# GBA register map
File version: 0.5
Registers are 16-bit, read-write, reset 0x0 unless marked. A register's access mark holds for its fields unless they carry their own. Offsets are from the block's base; [hi:lo] are bit positions; {n}, {i} and the like mark numbered series.

## SerialCommunication — GBA Communication Ports
Base 0x04000120
{0x0+2i} SIOMULTI{i} (i=0..3) — These registers are automatically reset to FFFFh upon transfer start.After transfer, these registers contain incoming data (16bit each) from all remote GBAs (if any / otherwise still FFFFh), as well as the local outgoing SIOMLT_SEND data.Ie. after the transfer, all connected GBAs will contain the same values in their SIOMULTI0-3 registers.
0x00 SIODATA32 32-bit (alternate view of SIOMULTI0) — Same as SIODATA8, for 32bit normal transfer mode respectively.
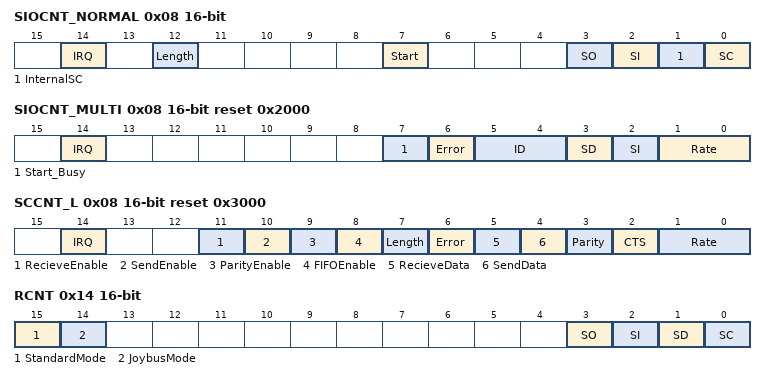
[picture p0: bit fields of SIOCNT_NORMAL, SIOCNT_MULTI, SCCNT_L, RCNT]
0x08 SIOCNT_NORMAL — SIO Control, usage in NORMAL Mode
  [14] IRQ — IRQ Enable
    0=Disable; 1=Enables IRQ upon completion
  [12] Length — Transfer Length
    0=Data8; 1=Data32
  [7] Start — Start Bit
    0=Inactive_Ready; 1=Start_Active
  [3] SO — SO during inactivity applied ONLY when Start is 0
    0=Low; 1=High
  [2] SI ro — SI State (opponents SO)
    0=Low; 1=High_None
  [1] InternalSC — Internal Shift Clock
    0=Low (256KHz); 1=High (2MHz)
  [0] SC — Shift Clock (SC)
    0=External; 1=Internal
0x08 SIOCNT_MULTI reset 0x2000 (alternate view of SIOCNT_NORMAL) — SIO Control, usage in NORMAL Mode
  [14] IRQ — IRQ Enable
    0=Disable; 1=Enables IRQ upon completion
  [7] Start_Busy — Start Busy Bit, read only for slaves
    0=Inactive; 1=Start_Busy
  [6] Error ro — Multi-Player Error
    0=None; 1=Error
  [5:4] ID ro — Multi-Player ID
    0=Parent; 1=Child1; 2=Child2; 3=Child3
  [3] SD ro — SD-Terminal
    0=None (Bad connection); 1=Some (All GBAs Ready)
  [2] SI ro — SI-Terminal
    0=Parent; 1=Child
  [1:0] Rate — Baud Rate
    0=r9600; 1=r38400; 2=r57600; 3=r115200
0x08 SCCNT_L reset 0x3000 (alternate view of SIOCNT_NORMAL) — SIO Control, usage in UART Mode
  [14] IRQ — IRQ Enable
    0=Disable; 1=Enables IRQ upon completion
  [11] RecieveEnable — Recieve Enable Flag
    0=Disable; 1=Enable
  [10] SendEnable — Send Enable Flag
    0=Disable; 1=Enable
  [9] ParityEnable — Parity Enable Flag
    0=Disable; 1=Enable
  [8] FIFOEnable — FIFO Enable Flag
    0=Disable; 1=Enable
  [7] Length — Data Length
    0=Data7 (7bits); 1=Data8 (8bits)
  [6] Error ro — Error Flag
    0=None; 1=Some
  [5] RecieveData ro — Revieve Data Flag
    0=NotEmpty; 1=Empty
  [4] SendData ro — Send Data Flag
    0=NotFull; 1=Full
  [3] Parity — Parity Control
    0=Even; 1=Odd
  [2] CTS — CTS Flag
    0=Blind (Send always/blindly); 1=Restricted (Send only when SC=LOW)
  [1:0] Rate — Baud Rate
    0=r9600; 1=r38400; 2=r57600; 3=r115200
0x0A SIOMLT_SEND — Outgoing data (16 bit) which is to be sent to the other GBAs.
0x0A SIODATA8 (alternate view of SIOMLT_SEND) — For 8bit normal mode. Contains 8bit data (only lower 8bit are used). Outgoing data should be written to this register before starting the transfer. During transfer, transmitted bits are shifted-out (MSB first), and received bits are shifted-in simultaneously. Upon transfer completion, the register contains the received 8bit value.
0x14 RCNT — Mode Selection, in Normal/Multiplayer/UART modes
  [15] StandardMode ro — Check Serial Mode
    0=Standard; 1=Joybus
  [14] JoybusMode ro — Must be 1 if in Joybus Mode with StandardMode to 1 too
    0=Disabled; 1=Enabled
  [3] SO ro — Current SO State
  [2] SI ro — Current SI State
  [1] SD ro — Current SD State
  [0] SC ro — Current SC State
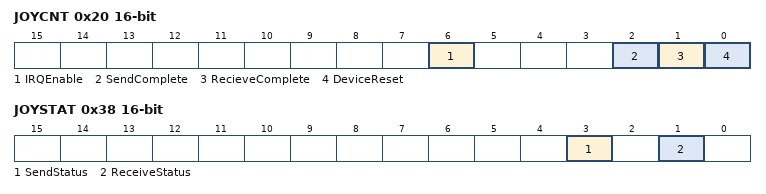
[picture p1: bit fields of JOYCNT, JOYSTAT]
0x20 JOYCNT — JOY BUS Control Register
  [6] IRQEnable — SIRQ when receiving a Device Reset Command
    0=Disable; 1=Enable
  [2] SendComplete — Send Complete Flag (Command 15h or 14h?) (Read/Acknowledge)
  [1] RecieveComplete — Receive Complete Flag (Command 14h or 15h?) (Read/Acknowledge)
  [0] DeviceReset — Device Reset Flag (Command FFh) (Read/Acknowledge)
0x30 JOY_RECV 32-bit — Receive Data Register
0x34 JOY_TRANS 32-bit — Transfer Data Register
0x38 JOYSTAT ro — Receive Status Register
  [3] SendStatus — Send Status Flag (1=Remote GBA is/was sending)
  [1] ReceiveStatus — Receive Status Flag (0=Remote GBA is/was receiving)
